AUTOSAR XML (schema 4-3-0)
package /ComponentTypes
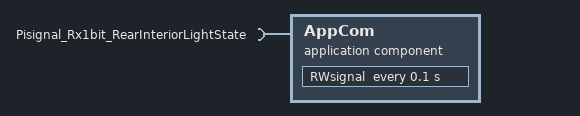
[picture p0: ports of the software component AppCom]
  application sw component type AppCom
    require port Pisignal_Rx1bit_RearInteriorLightState: nonqueued-receiver-com-spec{data-element=RearInteriorLightState, filter=data-filter-type=ALWAYS, init-value=0}, required-interface=Pisignal_Rx1bit_RearInteriorLightState
    behavior AppCom_InternalBehavior: data-type-mapping=SignalDataTypeMappingSet
      timing event TMT_RWsignal: start-on-event=RWsignal, period=0.1
      runnable RWsignal
        data-receive-point-by-arguments:
          access REC_Pisignal_Rx1bit_RearInteriorLightState_RearInteriorLightState: accessed-variable=Pisignal_Rx1bit_RearInteriorLightState.RearInteriorLightState
  swc implementation AppCom_Implementation: behavior=AppCom_InternalBehavior
